VERSION "CAN1"

NS_ :

BS_:

BU_: SCU Diagnostics Gateway HCU Tester TBOX SCS

BO_ 1913 DIAG_PhysResp_SCU: 8 SCU
 SG_ DiagnosticRespSCU : 7|64@0+ (1,0) [0|0] ""  Diagnostics

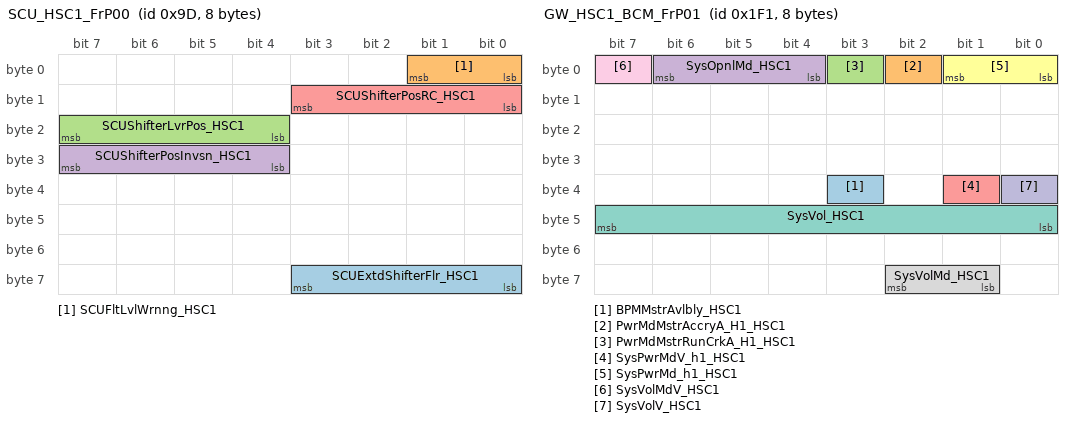
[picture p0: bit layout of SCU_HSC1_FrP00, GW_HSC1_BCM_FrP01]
BO_ 157 SCU_HSC1_FrP00: 8 SCU
 SG_ SCUExtdShifterFlr_HSC1 : 59|4@0+ (1,0) [0|15] ""  Gateway,HCU,Tester
 SG_ SCUFltLvlWrnng_HSC1 : 1|2@0+ (1,0) [0|3] ""  Tester
 SG_ SCUShifterLvrPos_HSC1 : 23|4@0+ (1,0) [0|15] ""  Gateway,HCU,TBOX
 SG_ SCUShifterPosInvsn_HSC1 : 31|4@0+ (1,0) [0|15] ""  HCU
 SG_ SCUShifterPosRC_HSC1 : 11|4@0+ (1,0) [0|15] ""  HCU

BO_ 1794 SCU_HSC1_FrS00: 7 SCU
 SG_ DTCInfomationSCU_HSC1 : 7|56@0+ (1,0) [0|0] ""  Gateway

BO_ 2015 DIAG_FuncReq_HSC1: 8 Diagnostics
 SG_ DiagnosticFuncAddrReq_h1 : 7|64@0+ (1,0) [0|0] ""  SCU

BO_ 1905 DIAG_PhysReq_SCU: 8 Diagnostics
 SG_ DiagnosticReqSCU_h1 : 7|64@0+ (1,0) [0|0] ""  SCU

BO_ 497 GW_HSC1_BCM_FrP01: 8 Gateway
 SG_ BPMMstrAvlbly_HSC1 : 35|1@0+ (1,0) [0|1] ""  SCU
 SG_ PwrMdMstrAccryA_H1_HSC1 : 2|1@0+ (1,0) [0|1] ""  SCU
 SG_ PwrMdMstrRunCrkA_H1_HSC1 : 3|1@0+ (1,0) [0|1] ""  SCU
 SG_ SysOpnlMd_HSC1 : 6|3@0+ (1,0) [0|7] ""  SCU
 SG_ SysPwrMdV_h1_HSC1 : 33|1@0+ (1,0) [0|1] ""  SCU
 SG_ SysPwrMd_h1_HSC1 : 1|2@0+ (1,0) [0|3] ""  SCU
 SG_ SysVol_HSC1 : 47|8@0+ (0.1,3) [3|28.5] ""  SCU
 SG_ SysVolMd_HSC1 : 58|2@0+ (1,0) [0|3] ""  SCU
 SG_ SysVolMdV_HSC1 : 7|1@0+ (1,0) [0|1] ""  SCU
 SG_ SysVolV_HSC1 : 32|1@0+ (1,0) [0|1] ""  SCU

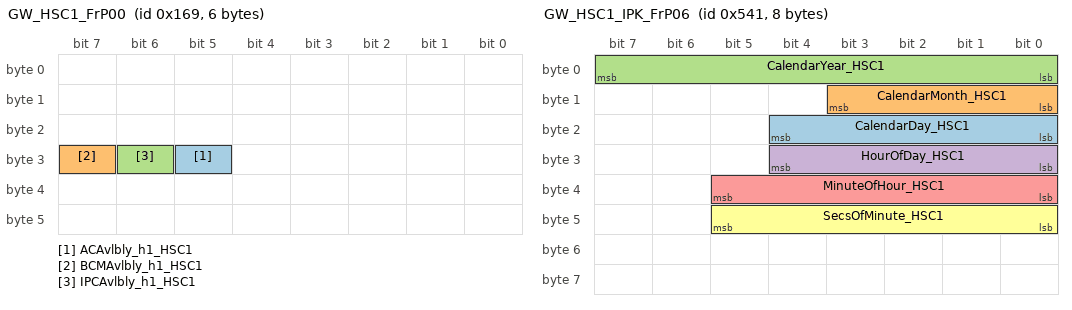
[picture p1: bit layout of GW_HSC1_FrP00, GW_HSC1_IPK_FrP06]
BO_ 361 GW_HSC1_FrP00: 6 Gateway
 SG_ ACAvlbly_h1_HSC1 : 29|1@0+ (1,0) [0|1] ""  SCU
 SG_ BCMAvlbly_h1_HSC1 : 31|1@0+ (1,0) [0|1] ""  SCU
 SG_ IPCAvlbly_h1_HSC1 : 30|1@0+ (1,0) [0|1] ""  SCU

BO_ 1344 GW_HSC1_FrP07: 8 Gateway
 SG_ VehOdoV_h1_HSC1 : 31|1@0+ (1,0) [0|1] ""  SCU
 SG_ VehOdo_h1_HSC1 : 7|24@0+ (1,0) [0|16777200] ""  SCU

BO_ 1345 GW_HSC1_IPK_FrP06: 8 Gateway
 SG_ CalendarDay_HSC1 : 20|5@0+ (1,0) [0|31] ""  SCU
 SG_ CalendarMonth_HSC1 : 11|4@0+ (1,0) [0|15] ""  SCU
 SG_ CalendarYear_HSC1 : 7|8@0+ (1,2000) [2000|2255] ""  SCU
 SG_ HourOfDay_HSC1 : 28|5@0+ (1,0) [0|23] ""  SCU
 SG_ MinuteOfHour_HSC1 : 37|6@0+ (1,0) [0|59] ""  SCU
 SG_ SecsOfMinute_HSC1 : 45|6@0+ (1,0) [0|59] ""  SCU

BO_ 498 GW_HSC1_IPK_FrP07: 2 Gateway
 SG_ SysBPM_HSC1 : 5|2@0+ (1,0) [0|3] ""  SCU
 SG_ SysBPMEnbd_HSC1 : 6|1@0+ (1,0) [0|1] ""  SCU

BO_ 175 HCU_HSC1_FrP00: 8 HCU
 SG_ EPTStCmdOn_HSC1 : 17|1@0+ (1,0) [0|1] ""  SCU

BO_ 406 HCU_HSC1_FrP01: 8 HCU
 SG_ EPTRdy_HSC1 : 38|1@0+ (1,0) [0|1] ""  SCU

BO_ 404 HCU_HSC1_FrP02: 8 HCU
 SG_ TrShftLvrPos_HSC1 : 27|4@0+ (1,0) [0|15] ""  SCU
 SG_ TrShftLvrPosV_HSC1 : 28|1@0+ (1,0) [0|1] ""  SCU

BO_ 851 SCS_HSC1_FrP15: 8 SCS
 SG_ VehSpdAvgDrvn_HSC1 : 6|15@0+ (0.015625,0) [0|511.984] ""  SCU
 SG_ VehSpdAvgDrvnV_HSC1 : 7|1@0+ (1,0) [0|1] ""  SCU

CM_ SG_ 1913 DiagnosticRespSCU "Diagnostic response from SCU";
CM_ SG_ 1794 DTCInfomationSCU_HSC1 "DTC Infomation of SCU

The length of DTC information signal is 7 bytes.
Byte 0 is MSB (most significant byte), and Byte 6 is LSB (least significant byte).
For each byte, Bit 7 is msb (most significant bit), and Bit 0 is lsb (least significant bit).

Byte 0:
Bit (7-4): DTC Serious Level
Bit (3-0): Reserved

Byte 1:
Bit (7-0): Reserved

Byte 2:
Bit (7-0): DTCHighByte

Byte 3:
Bit (7-0): DTCLowByte

Byte 4:
Bit (7-0): DTCFailureTypeByte

Byte 5:
Bit 7: warningIndicatorRequested
Bit 6: testNotCompletedThisOperationCycle
Bit 5: testFailedSinceLastClear
Bit 4: testNotCompletedSinceLastClear
Bit 3: confirmedDTC
Bit 2: pendingDTC
Bit 1: testFailedThisOperationCycle
Bit 0: testFailed

Byte 6:
Bit (7-0): DTC Type

For more detail, please refer to SMTC 2 800 004.
";
CM_ SG_ 2015 DiagnosticFuncAddrReq_h1 "Diagnostic functional address request";
CM_ SG_ 1905 DiagnosticReqSCU_h1 "Diagnostic request to SCU";
CM_ SG_ 497 BPMMstrAvlbly_HSC1 "Backup Power Mode Master Availability";
CM_ SG_ 497 PwrMdMstrAccryA_H1_HSC1 "Power Mode Master Accessory Terminal Status";
CM_ SG_ 497 PwrMdMstrRunCrkA_H1_HSC1 "Power Mode Master Run Crank Terminal Status";
CM_ SG_ 497 SysOpnlMd_HSC1 "System Operational Mode";
CM_ SG_ 497 SysPwrMdV_h1_HSC1 "System Power Mode Validity ";
CM_ SG_ 497 SysPwrMd_h1_HSC1 "System Power Mode";
CM_ SG_ 497 SysVol_HSC1 "Battery Voltage";
CM_ SG_ 497 SysVolMd_HSC1 "System Voltage Mode ";
CM_ SG_ 497 SysVolMdV_HSC1 "System Voltage Mode Validity ";
CM_ SG_ 497 SysVolV_HSC1 "Battery Voltage Validity";
CM_ SG_ 361 ACAvlbly_h1_HSC1 "AC Available

Detect if specific ECU is available according to node missing strategy by gateway ECU.

";
CM_ SG_ 361 BCMAvlbly_h1_HSC1 "BCM Available

Detect if specific ECU is available according to node missing strategy by gateway ECU.
";
CM_ SG_ 361 IPCAvlbly_h1_HSC1 "IPC Available

Detect if specific ECU is available according to node missing strategy by gateway ECU.

";
CM_ SG_ 1344 VehOdoV_h1_HSC1 "Vehicle Odometer Validity";
CM_ SG_ 1344 VehOdo_h1_HSC1 "Vehicle Odometer";
CM_ SG_ 1345 CalendarDay_HSC1 "current day info.";
CM_ SG_ 1345 CalendarMonth_HSC1 "current month info.";
CM_ SG_ 1345 CalendarYear_HSC1 "current year info";
CM_ SG_ 1345 HourOfDay_HSC1 "Hour Of Day.
current Hour info.";
CM_ SG_ 1345 MinuteOfHour_HSC1 "Minute Of Hour.
current Minute info.";
CM_ SG_ 1345 SecsOfMinute_HSC1 "Seconds Of Minute
current Second info.";
CM_ SG_ 498 SysBPM_HSC1 "System Backup Power Mode";
CM_ SG_ 498 SysBPMEnbd_HSC1 "System Backup Power Mode Enabled";
CM_ SG_ 175 EPTStCmdOn_HSC1 "Electric Powertrain Start Command On";
CM_ SG_ 406 EPTRdy_HSC1 "Electric Powertrain Ready";
CM_ SG_ 404 TrShftLvrPos_HSC1 "Transmission Shift Lever Position

For DCT/AT transmission :
$0=Between Ranges
$1=Park Range
$2=Reverse Range
$3=Neutral Range
$4=Forward Range A
$5=Forward Range B
$6=Forward Range C
$7=Forward Range D
$8=Forward Range E
$9=Forward Range F
$A=Forward Range G
$B=Forward Range H
$F=Lever Position Unknown

For Manual Transmission: only below status are used
$2=Reverse Range
$3=Neutral Range (Validity on MT vehicles is only protected for Neutral range)
$F=Lever Position Unknown";
CM_ SG_ 404 TrShftLvrPosV_HSC1 "Transmission Shift Lever Position Validity";
CM_ SG_ 851 VehSpdAvgDrvn_HSC1 "Vehicle Speed Average Driven";
CM_ SG_ 851 VehSpdAvgDrvnV_HSC1 "Vehicle Speed Average Driven Validity";
BA_DEF_  "BaudRate" FLOAT 1000 1000000;
BA_DEF_ SG_  "GenSigLongName" STRING ;
BA_DEF_ BO_  "GenMsgSendType" ENUM  "cyclic","spontaneous","cyclicIfActive","spontaneousWithDelay","OnChangeWithRepetition","Immediate";
BA_DEF_ BO_  "GenMsgCycleTime" FLOAT 0 300000;
BA_DEF_ SG_  "GenSigStartValue" INT -9.22337203685478E+018 1.84467440737096E+019;
BA_DEF_DEF_  "BaudRate" 1000;
BA_DEF_DEF_  "GenSigLongName" "";
BA_DEF_DEF_  "GenMsgSendType" "";
BA_DEF_DEF_  "GenMsgCycleTime" 0;
BA_DEF_DEF_  "GenSigStartValue" 0;
BA_ "BaudRate" 500000;
BA_ "GenMsgSendType" BO_ 1913 5;
BA_ "GenMsgCycleTime" BO_ 157 10;
BA_ "GenMsgSendType" BO_ 157 0;
BA_ "GenMsgSendType" BO_ 1794 1;
BA_ "GenMsgSendType" BO_ 2015 5;
BA_ "GenMsgSendType" BO_ 1905 5;
BA_ "GenMsgCycleTime" BO_ 497 20;
BA_ "GenMsgSendType" BO_ 497 0;
BA_ "GenMsgCycleTime" BO_ 361 20;
BA_ "GenMsgSendType" BO_ 361 0;
BA_ "GenMsgCycleTime" BO_ 1344 1000;
BA_ "GenMsgSendType" BO_ 1344 0;
BA_ "GenMsgCycleTime" BO_ 1345 200;
BA_ "GenMsgSendType" BO_ 1345 0;
BA_ "GenMsgCycleTime" BO_ 498 20;
BA_ "GenMsgSendType" BO_ 498 0;
BA_ "GenMsgCycleTime" BO_ 175 10;
BA_ "GenMsgSendType" BO_ 175 0;
BA_ "GenMsgCycleTime" BO_ 406 20;
BA_ "GenMsgSendType" BO_ 406 0;
BA_ "GenMsgCycleTime" BO_ 404 20;
BA_ "GenMsgSendType" BO_ 404 0;
BA_ "GenMsgCycleTime" BO_ 851 100;
BA_ "GenMsgSendType" BO_ 851 0;
BA_ "GenSigLongName" SG_ 157 SCUExtdShifterFlr_HSC1 "Shifter Control Unit Extended Shifter Failure";
BA_ "GenSigLongName" SG_ 157 SCUFltLvlWrnng_HSC1 "Shifer Control Unit Fault Level Warning";
BA_ "GenSigLongName" SG_ 157 SCUShifterLvrPos_HSC1 "Shifter Control Unit Shifter Lever Position";
BA_ "GenSigLongName" SG_ 157 SCUShifterPosInvsn_HSC1 "Shifter Control Unit Shifter Position Inversion";
BA_ "GenSigStartValue" SG_ 157 SCUShifterPosInvsn_HSC1 15;
BA_ "GenSigLongName" SG_ 157 SCUShifterPosRC_HSC1 "Shifter Control Unit Shifter Position Rolling Counter";
VAL_ 157 SCUExtdShifterFlr_HSC1 13 "Motor fail" 12 "Motor Stuck" 11 "All SENT sensor fail" 10 "Single SENT sensor fail" 9 "All unlock button fail" 8 "Single Unlock button fail" 7 "SSU fail" 6 "All P button sensor fail" 5 "All rotary hall sensor fail" 4 "Single P button sensor fail" 3 "CAN Bus communication fail" 2 "Single rotary hall sensor fail" 1 "Mode selector sensor fail" 0 "No fail" ;
VAL_ 157 SCUFltLvlWrnng_HSC1 2 "SCU Critical Fault" 1 "SCU Limited Fault" 0 "No Fault" ;
VAL_ 157 SCUShifterLvrPos_HSC1 10 "Error" 9 "Reserved" 8 "P(Park)" 7 "R(Reverse)" 6 "N(Neutral)" 5 "D(Drive)" 3 "M(Manual mode)" 2 "W(Winter mode)" 1 "S(Sport mode)" 0 "SCU initialization" ;
VAL_ 157 SCUShifterPosInvsn_HSC1 15 "SCU initialization" 14 "S(Sport mode)" 13 "W(Winter mode)" 12 "M(Manual mode)" 11 "Reserved" 10 "D(Drive)" 9 "N(Neutral)" 8 "R(Reverse)" 7 "P(Park)" 6 "Reserved" 5 "Error" ;
VAL_ 497 BPMMstrAvlbly_HSC1 1 "TRUE" 0 "FALSE" ;
VAL_ 497 PwrMdMstrAccryA_H1_HSC1 1 "Active" 0 "Inactive" ;
VAL_ 497 PwrMdMstrRunCrkA_H1_HSC1 1 "Active" 0 "Inactive" ;
VAL_ 497 SysOpnlMd_HSC1 5 "Diagnosic or Reprogramming(Reserve)" 4 "Storage Mode" 3 "Show Room" 2 "Transit Mode" 1 "Manufacturing Mode" 0 "Normal Mode" ;
VAL_ 497 SysPwrMdV_h1_HSC1 1 "Invalid" 0 "Valid" ;
VAL_ 497 SysPwrMd_h1_HSC1 3 "Crank" 2 "Run" 1 "ACC" 0 "Off" ;
VAL_ 497 SysVolMd_HSC1 3 "Illegal System  Voltage" 2 "High System Voltage" 1 "Low System Voltage" 0 "Normal" ;
VAL_ 497 SysVolMdV_HSC1 1 "Invalid" 0 "Valid" ;
VAL_ 497 SysVolV_HSC1 1 "Invalid" 0 "Valid" ;
VAL_ 361 ACAvlbly_h1_HSC1 1 "TRUE" 0 "FALSE" ;
VAL_ 361 BCMAvlbly_h1_HSC1 1 "TRUE" 0 "FALSE" ;
VAL_ 361 IPCAvlbly_h1_HSC1 1 "TRUE" 0 "FALSE" ;
VAL_ 1344 VehOdoV_h1_HSC1 1 "Invalid" 0 "Valid" ;
VAL_ 1345 CalendarMonth_HSC1 15 "Reserved" 14 "Reserved" 13 "Reserved" 12 "December" 11 "November" 10 "October" 9 "September" 8 "August" 7 "July" 6 "June" 5 "May" 4 "April" 3 "March" 2 "February" 1 "January" 0 "Unknown" ;
VAL_ 498 SysBPM_HSC1 3 "Crank" 2 "Run" 1 "ACC" 0 "Off" ;
VAL_ 498 SysBPMEnbd_HSC1 1 "TRUE" 0 "FALSE" ;
VAL_ 175 EPTStCmdOn_HSC1 1 "TRUE" 0 "FALSE" ;
VAL_ 406 EPTRdy_HSC1 1 "Ready" 0 "Not Ready" ;
VAL_ 404 TrShftLvrPos_HSC1 15 "Lever Position Unknown" 11 "Forward Range H" 10 "Forward Range G" 9 "Forward Range F" 8 "Forward Range E" 7 "Forward Range D" 6 "Forward Range C" 5 "Forward Range B" 4 "Forward Range A" 3 "Neutral Range" 2 "Reverse Range" 1 "Park Range" 0 "Between Ranges" ;
VAL_ 404 TrShftLvrPosV_HSC1 1 "Invalid" 0 "Valid" ;
VAL_ 851 VehSpdAvgDrvnV_HSC1 1 "Invalid" 0 "Valid" ;
